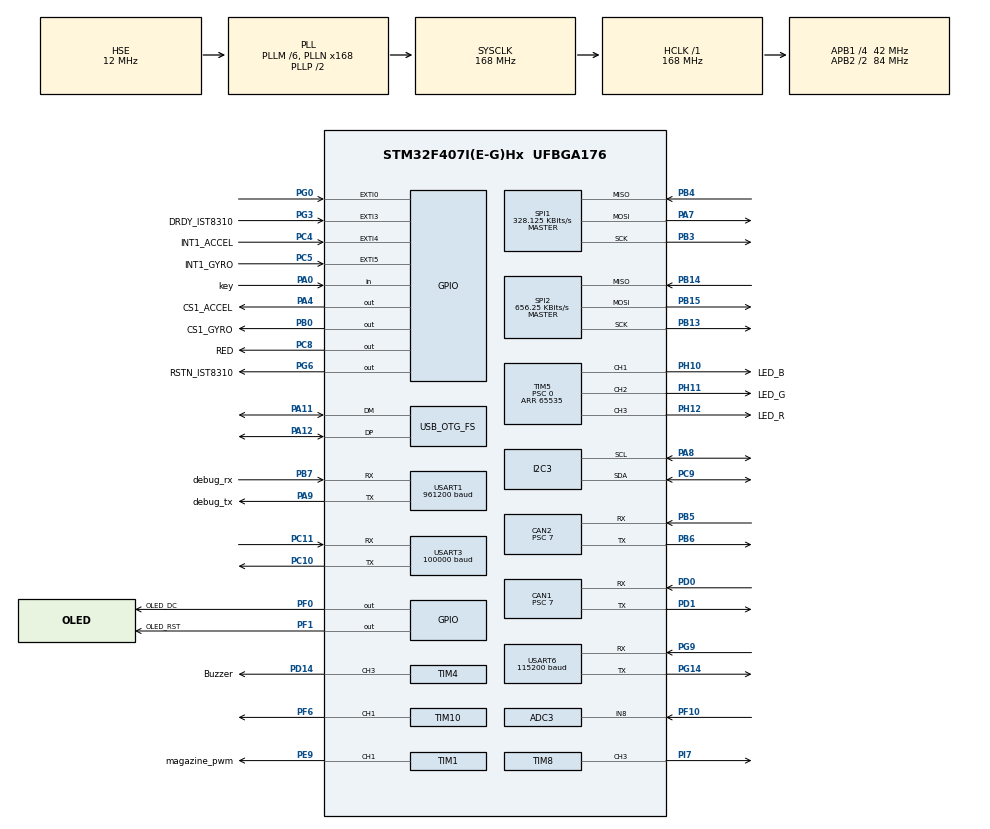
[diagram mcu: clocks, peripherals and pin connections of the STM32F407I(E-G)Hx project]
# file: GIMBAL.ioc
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ADC1.Channel-0\#ChannelRegularConversion=ADC_CHANNEL_TEMPSENSOR
ADC1.NbrOfConversionFlag=1
ADC1.Rank-0\#ChannelRegularConversion=1
ADC1.SamplingTime-0\#ChannelRegularConversion=ADC_SAMPLETIME_3CYCLES
ADC1.master=1
ADC3.Channel-0\#ChannelRegularConversion=ADC_CHANNEL_8
ADC3.NbrOfConversionFlag=1
ADC3.Rank-0\#ChannelRegularConversion=1
ADC3.SamplingTime-0\#ChannelRegularConversion=ADC_SAMPLETIME_3CYCLES
CAN1.ABOM=ENABLE
CAN1.AWUM=ENABLE
CAN1.BS1=CAN_BS1_3TQ
CAN1.BS2=CAN_BS2_2TQ
CAN1.CalculateTimeQuantum=166.66666666666669
CAN1.NART=ENABLE
CAN1.Prescaler=7
CAN2.ABOM=ENABLE
CAN2.AWUM=ENABLE
CAN2.BS1=CAN_BS1_3TQ
CAN2.BS2=CAN_BS2_2TQ
CAN2.CalculateTimeQuantum=166.66666666666669
CAN2.Prescaler=7
Dma.Request0=SPI1_RX
Dma.Request1=SPI1_TX
Dma.Request2=USART1_TX
Dma.Request3=USART3_RX
Dma.Request4=USART1_RX
Dma.Request5=USART6_RX
Dma.Request6=USART6_TX
Dma.Request7=TIM8_CH3
Dma.SPI1_RX.0.Direction=DMA_PERIPH_TO_MEMORY
Dma.SPI1_RX.0.FIFOMode=DMA_FIFOMODE_DISABLE
Dma.SPI1_RX.0.Instance=DMA2_Stream2
Dma.SPI1_RX.0.MemDataAlignment=DMA_MDATAALIGN_BYTE
Dma.SPI1_RX.0.MemInc=DMA_MINC_ENABLE
Dma.SPI1_RX.0.Mode=DMA_NORMAL
Dma.SPI1_RX.0.PeriphDataAlignment=DMA_PDATAALIGN_BYTE
Dma.SPI1_RX.0.PeriphInc=DMA_PINC_DISABLE
Dma.SPI1_RX.0.Priority=DMA_PRIORITY_VERY_HIGH
Dma.SPI1_TX.1.Direction=DMA_MEMORY_TO_PERIPH
Dma.SPI1_TX.1.FIFOMode=DMA_FIFOMODE_DISABLE
Dma.SPI1_TX.1.Instance=DMA2_Stream3
Dma.SPI1_TX.1.MemDataAlignment=DMA_MDATAALIGN_BYTE
Dma.SPI1_TX.1.MemInc=DMA_MINC_ENABLE
Dma.SPI1_TX.1.Mode=DMA_NORMAL
Dma.SPI1_TX.1.PeriphDataAlignment=DMA_PDATAALIGN_BYTE
Dma.SPI1_TX.1.PeriphInc=DMA_PINC_DISABLE
Dma.SPI1_TX.1.Priority=DMA_PRIORITY_HIGH
Dma.TIM8_CH3.7.Direction=DMA_MEMORY_TO_PERIPH
Dma.TIM8_CH3.7.FIFOMode=DMA_FIFOMODE_DISABLE
Dma.TIM8_CH3.7.Instance=DMA2_Stream4
Dma.TIM8_CH3.7.MemDataAlignment=DMA_MDATAALIGN_HALFWORD
Dma.TIM8_CH3.7.MemInc=DMA_MINC_ENABLE
Dma.TIM8_CH3.7.Mode=DMA_NORMAL
Dma.TIM8_CH3.7.PeriphDataAlignment=DMA_PDATAALIGN_HALFWORD
Dma.TIM8_CH3.7.PeriphInc=DMA_PINC_DISABLE
Dma.TIM8_CH3.7.Priority=DMA_PRIORITY_LOW
Dma.USART1_RX.4.Direction=DMA_PERIPH_TO_MEMORY
Dma.USART1_RX.4.FIFOMode=DMA_FIFOMODE_DISABLE
Dma.USART1_RX.4.Instance=DMA2_Stream5
Dma.USART1_RX.4.MemDataAlignment=DMA_MDATAALIGN_BYTE
Dma.USART1_RX.4.MemInc=DMA_MINC_ENABLE
Dma.USART1_RX.4.Mode=DMA_CIRCULAR
Dma.USART1_RX.4.PeriphDataAlignment=DMA_PDATAALIGN_BYTE
Dma.USART1_RX.4.PeriphInc=DMA_PINC_DISABLE
Dma.USART1_RX.4.Priority=DMA_PRIORITY_LOW
Dma.USART1_TX.2.Direction=DMA_MEMORY_TO_PERIPH
Dma.USART1_TX.2.FIFOMode=DMA_FIFOMODE_DISABLE
Dma.USART1_TX.2.Instance=DMA2_Stream7
Dma.USART1_TX.2.MemDataAlignment=DMA_MDATAALIGN_BYTE
Dma.USART1_TX.2.MemInc=DMA_MINC_ENABLE
Dma.USART1_TX.2.Mode=DMA_NORMAL
Dma.USART1_TX.2.PeriphDataAlignment=DMA_PDATAALIGN_BYTE
Dma.USART1_TX.2.PeriphInc=DMA_PINC_DISABLE
Dma.USART1_TX.2.Priority=DMA_PRIORITY_LOW
Dma.USART3_RX.3.Direction=DMA_PERIPH_TO_MEMORY
Dma.USART3_RX.3.FIFOMode=DMA_FIFOMODE_DISABLE
Dma.USART3_RX.3.Instance=DMA1_Stream1
Dma.USART3_RX.3.MemDataAlignment=DMA_MDATAALIGN_BYTE
Dma.USART3_RX.3.MemInc=DMA_MINC_ENABLE
Dma.USART3_RX.3.Mode=DMA_CIRCULAR
Dma.USART3_RX.3.PeriphDataAlignment=DMA_PDATAALIGN_BYTE
Dma.USART3_RX.3.PeriphInc=DMA_PINC_DISABLE
Dma.USART3_RX.3.Priority=DMA_PRIORITY_MEDIUM
Dma.USART6_RX.5.Direction=DMA_PERIPH_TO_MEMORY
Dma.USART6_RX.5.FIFOMode=DMA_FIFOMODE_DISABLE
Dma.USART6_RX.5.Instance=DMA2_Stream1
Dma.USART6_RX.5.MemDataAlignment=DMA_MDATAALIGN_BYTE
Dma.USART6_RX.5.MemInc=DMA_MINC_ENABLE
Dma.USART6_RX.5.Mode=DMA_CIRCULAR
Dma.USART6_RX.5.PeriphDataAlignment=DMA_PDATAALIGN_BYTE
Dma.USART6_RX.5.PeriphInc=DMA_PINC_DISABLE
Dma.USART6_RX.5.Priority=DMA_PRIORITY_MEDIUM
Dma.USART6_TX.6.Direction=DMA_MEMORY_TO_PERIPH
Dma.USART6_TX.6.FIFOMode=DMA_FIFOMODE_DISABLE
Dma.USART6_TX.6.Instance=DMA2_Stream6
Dma.USART6_TX.6.MemDataAlignment=DMA_MDATAALIGN_BYTE
Dma.USART6_TX.6.MemInc=DMA_MINC_ENABLE
Dma.USART6_TX.6.Mode=DMA_NORMAL
Dma.USART6_TX.6.PeriphDataAlignment=DMA_PDATAALIGN_BYTE
Dma.USART6_TX.6.PeriphInc=DMA_PINC_DISABLE
Dma.USART6_TX.6.Priority=DMA_PRIORITY_HIGH
FREERTOS.INCLUDE_eTaskGetState=1
FREERTOS.INCLUDE_pcTaskGetTaskName=1
FREERTOS.INCLUDE_uxTaskGetStackHighWaterMark=1
FREERTOS.INCLUDE_vTaskCleanUpResources=1
FREERTOS.INCLUDE_vTaskDelayUntil=1
FREERTOS.INCLUDE_xEventGroupSetBitFromISR=1
FREERTOS.INCLUDE_xQueueGetMutexHolder=1
FREERTOS.INCLUDE_xSemaphoreGetMutexHolder=1
FREERTOS.INCLUDE_xTaskAbortDelay=1
FREERTOS.INCLUDE_xTaskGetCurrentTaskHandle=1
FREERTOS.INCLUDE_xTaskGetHandle=1
FREERTOS.INCLUDE_xTimerPendFunctionCall=1
FREERTOS.Tasks01=test,0,128,test_task,As weak,NULL,Dynamic,NULL,NULL;Debug_Task,0,128,Debug,Default,NULL,Dynamic,NULL,NULL;IMU_Send_Task,2,128,IMU_Send,Default,NULL,Dynamic,NULL,NULL;Can2_Rei_Task,1,128,Can2_Reivece,Default,NULL,Dynamic,NULL,NULL;CAN1,1,128,CAN1_R,Default,NULL,Dynamic,NULL,NULL
FREERTOS.configTOTAL_HEAP_SIZE=24576
I2C3.I2C_Mode=I2C_Fast
Mcu.Family=STM32F4
Mcu.Name=STM32F407I(E-G)Hx
Mcu.Package=UFBGA176
NVIC.CAN1_RX0_IRQn=true\:5\:0\:true\:false\:true\:true\:true\:true
NVIC.CAN2_RX0_IRQn=true\:5\:0\:true\:false\:true\:true\:true\:true
NVIC.DMA1_Stream1_IRQn=true\:0\:0\:false\:false\:true\:false\:true\:true
NVIC.DMA2_Stream1_IRQn=true\:0\:0\:false\:false\:true\:true\:false\:true
NVIC.DMA2_Stream2_IRQn=true\:5\:0\:true\:false\:false\:false\:false\:false
NVIC.DMA2_Stream3_IRQn=true\:5\:0\:true\:false\:false\:true\:false\:true
NVIC.DMA2_Stream4_IRQn=true\:0\:0\:false\:false\:true\:true\:false\:true
NVIC.DMA2_Stream5_IRQn=true\:0\:0\:false\:false\:true\:true\:false\:true
NVIC.DMA2_Stream6_IRQn=true\:0\:0\:false\:false\:true\:true\:false\:true
NVIC.DMA2_Stream7_IRQn=true\:0\:0\:false\:false\:true\:false\:true\:true
NVIC.EXTI0_IRQn=true\:6\:0\:true\:false\:true\:true\:true\:true
NVIC.EXTI3_IRQn=true\:5\:0\:true\:false\:true\:true\:true\:true
NVIC.EXTI4_IRQn=true\:5\:0\:true\:false\:true\:true\:true\:true
NVIC.EXTI9_5_IRQn=true\:5\:0\:true\:false\:true\:true\:true\:true
NVIC.OTG_FS_IRQn=true\:5\:0\:true\:false\:true\:true\:true\:true
NVIC.PriorityGroup=NVIC_PRIORITYGROUP_4
NVIC.TIM3_IRQn=true\:7\:0\:true\:false\:true\:true\:true\:true
NVIC.TIM6_DAC_IRQn=true\:0\:0\:false\:false\:true\:false\:true\:true
NVIC.TimeBase=TIM6_DAC_IRQn
NVIC.TimeBaseIP=TIM6
NVIC.USART1_IRQn=true\:6\:0\:true\:false\:true\:true\:true\:true
NVIC.USART3_IRQn=true\:6\:0\:true\:false\:true\:true\:true\:true
NVIC.USART6_IRQn=true\:6\:0\:true\:false\:true\:true\:true\:true
PA0-WKUP.GPIO_Label=key
PA0-WKUP.GPIO_PuPd=GPIO_PULLUP
PA0-WKUP.Signal=GPIO_Input
PA11.Mode=Device_Only
PA11.Signal=USB_OTG_FS_DM
PA12.Mode=Device_Only
PA12.Signal=USB_OTG_FS_DP
PA13.Mode=Serial_Wire
PA13.Signal=SYS_JTMS-SWDIO
PA14.Mode=Serial_Wire
PA14.Signal=SYS_JTCK-SWCLK
PA4.GPIO_Label=CS1_ACCEL
PA4.GPIO_PuPd=GPIO_PULLUP
PA4.GPIO_Speed=GPIO_SPEED_FREQ_HIGH
PA4.PinState=GPIO_PIN_SET
PA4.Signal=GPIO_Output
PA7.GPIO_PuPd=GPIO_PULLUP
PA7.Mode=Full_Duplex_Master
PA7.Signal=SPI1_MOSI
PA8.Mode=I2C
PA8.Signal=I2C3_SCL
PA9.GPIO_Label=debug_tx
PA9.Mode=Asynchronous
PA9.Signal=USART1_TX
PB0.GPIO_Label=CS1_GYRO
PB0.GPIO_PuPd=GPIO_PULLUP
PB0.GPIO_Speed=GPIO_SPEED_FREQ_HIGH
PB0.PinState=GPIO_PIN_SET
PB0.Signal=GPIO_Output
PB12.Signal=SPI2_NSS
PB13.Mode=Full_Duplex_Master
PB13.Signal=SPI2_SCK
PB14.Mode=Full_Duplex_Master
PB14.Signal=SPI2_MISO
PB15.Mode=Full_Duplex_Master
PB15.Signal=SPI2_MOSI
PB3.GPIO_PuPd=GPIO_PULLUP
PB3.Mode=Full_Duplex_Master
PB3.Signal=SPI1_SCK
PB4.GPIO_PuPd=GPIO_PULLUP
PB4.Mode=Full_Duplex_Master
PB4.Signal=SPI1_MISO
PB5.Mode=Slave
PB5.Signal=CAN2_RX
PB6.Mode=Slave
PB6.Signal=CAN2_TX
PB7.GPIO_Label=debug_rx
PB7.Mode=Asynchronous
PB7.Signal=USART1_RX
PC10.Mode=Asynchronous
PC10.Signal=USART3_TX
PC11.Mode=Asynchronous
PC11.Signal=USART3_RX
PC4.GPIO_Label=INT1_ACCEL
PC4.GPIO_ModeDefaultEXTI=GPIO_MODE_IT_FALLING
PC4.GPIO_PuPd=GPIO_PULLUP
PC4.Signal=GPXTI4
PC5.GPIO_Label=INT1_GYRO
PC5.GPIO_ModeDefaultEXTI=GPIO_MODE_IT_FALLING
PC5.GPIO_PuPd=GPIO_PULLUP
PC5.Signal=GPXTI5
PC8.GPIO_Label=RED
PC8.GPIO_PuPd=GPIO_NOPULL
PC8.GPIO_Speed=GPIO_SPEED_FREQ_MEDIUM
PC8.Signal=GPIO_Output
PC9.Mode=I2C
PC9.Signal=I2C3_SDA
PD0.Mode=Master
PD0.Signal=CAN1_RX
PD1.Mode=Master
PD1.Signal=CAN1_TX
PD14.GPIO_Label=Buzzer
PD14.Signal=S_TIM4_CH3
PE9.GPIO_Label=magazine_pwm
PE9.Signal=S_TIM1_CH1
PF0.GPIO_Label=OLED_DC
PF0.Signal=GPIO_Output
PF1.GPIO_Label=OLED_RST
PF1.Signal=GPIO_Output
PF10.Mode=IN8
PF10.Signal=ADC3_IN8
PF6.GPIO_PuPd=GPIO_PULLUP
PF6.GPIO_Speed=GPIO_SPEED_FREQ_HIGH
PF6.Signal=S_TIM10_CH1
PG0.GPIO_ModeDefaultEXTI=GPIO_MODE_IT_FALLING
PG0.GPIO_PuPd=GPIO_PULLUP
PG0.Signal=GPXTI0
PG14.Mode=Asynchronous
PG14.Signal=USART6_TX
PG3.GPIO_Label=DRDY_IST8310
PG3.GPIO_ModeDefaultEXTI=GPIO_MODE_IT_FALLING
PG3.GPIO_PuPd=GPIO_PULLUP
PG3.Signal=GPXTI3
PG6.GPIO_Label=RSTN_IST8310
PG6.GPIO_PuPd=GPIO_PULLUP
PG6.GPIO_Speed=GPIO_SPEED_FREQ_MEDIUM
PG6.PinState=GPIO_PIN_SET
PG6.Signal=GPIO_Output
PG9.Mode=Asynchronous
PG9.Signal=USART6_RX
PH0-OSC_IN.Mode=HSE-External-Oscillator
PH0-OSC_IN.Signal=RCC_OSC_IN
PH1-OSC_OUT.Mode=HSE-External-Oscillator
PH1-OSC_OUT.Signal=RCC_OSC_OUT
PH10.GPIO_Label=LED_B
PH10.GPIO_PuPd=GPIO_PULLUP
PH10.GPIO_Speed=GPIO_SPEED_FREQ_HIGH
PH10.Signal=S_TIM5_CH1
PH11.GPIO_Label=LED_G
PH11.GPIO_PuPd=GPIO_PULLUP
PH11.GPIO_Speed=GPIO_SPEED_FREQ_HIGH
PH11.Signal=S_TIM5_CH2
PH12.GPIO_Label=LED_R
PH12.GPIO_PuPd=GPIO_PULLUP
PH12.GPIO_Speed=GPIO_SPEED_FREQ_HIGH
PH12.Signal=S_TIM5_CH3
PI7.Signal=S_TIM8_CH3
ProjectManager.HeapSize=0x2000
ProjectManager.StackSize=0x2000
ProjectManager.TargetToolchain=MDK-ARM V5
RCC.48MHZClocksFreq_Value=48000000
RCC.AHBFreq_Value=168000000
RCC.APB1CLKDivider=RCC_HCLK_DIV4
RCC.APB1Freq_Value=42000000
RCC.APB1TimFreq_Value=84000000
RCC.APB2CLKDivider=RCC_HCLK_DIV2
RCC.APB2Freq_Value=84000000
RCC.APB2TimFreq_Value=168000000
RCC.CortexFreq_Value=168000000
RCC.HCLKFreq_Value=168000000
RCC.HSE_VALUE=12000000
RCC.HSI_VALUE=16000000
RCC.LSE_VALUE=32768
RCC.PLLM=6
RCC.PLLN=168
RCC.PLLQ=7
RCC.RCC_RTC_Clock_SourceVirtual=RCC_RTCCLKSOURCE_HSE_DIV30
RCC.RCC_RTC_Clock_Source_FROM_HSE=RCC_RTCCLKSOURCE_HSE_DIV30
RCC.SYSCLKFreq_VALUE=168000000
RCC.SYSCLKSource=RCC_SYSCLKSOURCE_PLLCLK
RCC.VCOOutputFreq_Value=336000000
SH.S_TIM10_CH1.0=TIM10_CH1,PWM Generation1 CH1
SH.S_TIM1_CH1.0=TIM1_CH1,PWM Generation1 CH1
SH.S_TIM4_CH3.0=TIM4_CH3,PWM Generation3 CH3
SH.S_TIM5_CH1.0=TIM5_CH1,PWM Generation1 CH1
SH.S_TIM5_CH2.0=TIM5_CH2,PWM Generation2 CH2
SH.S_TIM5_CH3.0=TIM5_CH3,PWM Generation3 CH3
SH.S_TIM8_CH3.0=TIM8_CH3,PWM Generation3 CH3
SPI1.BaudRatePrescaler=SPI_BAUDRATEPRESCALER_256
SPI1.CLKPhase=SPI_PHASE_2EDGE
SPI1.CLKPolarity=SPI_POLARITY_HIGH
SPI1.CalculateBaudRate=328.125 KBits/s
SPI1.Direction=SPI_DIRECTION_2LINES
SPI1.Mode=SPI_MODE_MASTER
SPI1.VirtualType=VM_MASTER
SPI2.BaudRatePrescaler=SPI_BAUDRATEPRESCALER_64
SPI2.CalculateBaudRate=656.25 KBits/s
SPI2.Direction=SPI_DIRECTION_2LINES
SPI2.Mode=SPI_MODE_MASTER
SPI2.VirtualType=VM_MASTER
TIM1.Channel-PWM\ Generation1\ CH1=TIM_CHANNEL_1
TIM1.Period=19999
TIM1.Prescaler=83
TIM10.Channel=TIM_CHANNEL_1
TIM10.Period=4999
TIM3.AutoReloadPreload=TIM_AUTORELOAD_PRELOAD_ENABLE
TIM3.Period=49
TIM3.Prescaler=83
TIM4.Channel-PWM\ Generation3\ CH3=TIM_CHANNEL_3
TIM4.Period=370
TIM4.Prescaler=130
TIM4.Pulse-PWM\ Generation3\ CH3=0
TIM5.Channel-PWM\ Generation1\ CH1=TIM_CHANNEL_1
TIM5.Channel-PWM\ Generation2\ CH2=TIM_CHANNEL_2
TIM5.Channel-PWM\ Generation3\ CH3=TIM_CHANNEL_3
TIM5.Period=65535
TIM5.Prescaler=0
TIM8.Channel-PWM\ Generation3\ CH3=TIM_CHANNEL_3
TIM8.Period=224
USART1.BaudRate=961200
USART1.VirtualMode=VM_ASYNC
USART3.BaudRate=100000
USART3.VirtualMode=VM_ASYNC
USART6.BaudRate=115200
USART6.VirtualMode=VM_ASYNC
USB_DEVICE.CLASS_NAME_FS=CDC
USB_DEVICE.VirtualMode-CDC_FS=Cdc
USB_DEVICE.VirtualModeFS=Cdc_FS
USB_OTG_FS.VirtualMode=Device_Only
VP_ADC1_TempSens_Input.Mode=IN-TempSens
VP_ADC1_Vref_Input.Mode=IN-Vrefint
VP_FREERTOS_VS_CMSIS_V1.Mode=CMSIS_V1
VP_SYS_VS_tim6.Mode=TIM6
VP_TIM10_VS_ClockSourceINT.Mode=Enable_Timer
VP_TIM1_VS_ClockSourceINT.Mode=Internal
VP_TIM3_VS_ClockSourceINT.Mode=Internal
VP_TIM4_VS_ClockSourceINT.Mode=Internal
VP_TIM5_VS_ClockSourceINT.Mode=Internal
VP_TIM8_VS_ClockSourceINT.Mode=Internal
VP_USB_DEVICE_VS_USB_DEVICE_CDC_FS.Mode=CDC_FS
board=custom

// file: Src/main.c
/* USER CODE BEGIN Header */
/**
  ******************************************************************************
  * @file           : main.c
  * @brief          : Main program body
  ******************************************************************************
  * @attention
  *
  * <h2><center>&copy; Copyright (c) 2019 STMicroelectronics.
  * All rights reserved.</center></h2>
  *
  * This software component is licensed by ST under Ultimate Liberty license
  * SLA0044, the "License"; You may not use this file except in compliance with
  * the License. You may obtain a copy of the License at:
  *                             www.st.com/SLA0044
  *
  ******************************************************************************
  */
/* USER CODE END Header */
#include "main.h"
#include "cmsis_os.h"
#include "adc.h"
#include "can.h"
#include "dma.h"
#include "i2c.h"
#include "spi.h"
#include "tim.h"
#include "usart.h"
#include "usb_device.h"
#include "gpio.h"

/* USER CODE BEGIN Includes */
#include "bsp_delay.h"

#include "calibrate_task.h"
#include "INS_task.h"
#include "led_flow_task.h"
#include "user_can.h"
#include "bsp_buzzer.h"
#include "stdbool.h"
#include "DR16_RECIVE.h"
#include "oled.h"
#include "bsp_adc.h"
#include "stdio.h"
#include "WS2812.h"

//#include "oledfont.h"
/* USER CODE END Includes */

void SystemClock_Config(void);
void MX_FREERTOS_Init(void);

/* USER CODE BEGIN 0 */
bool ins_ok=0;
int controul_times=0;
int ins_times=0;
int DR16_times=0;
int M2006_times=0;

int send_to_2006=0;
int M2006_targe_speed=0;
int beep_Val=0;

	int	send_to_SHOOT_R=0;
	int	send_to_SHOOT_L=0;

int SHOOT_L_speed=0;//左摩擦轮的目标速度   应该为负值
int SHOOT_R_speed=0;//右摩擦轮的目标速度

int yaw_trage_speed=0;
float yaw_trage_angle=0;
float yaw_trage_angle_1s_ago=0;
float yaw_trage_angle_add_1s=0;
float yaw_trage_angle_new=0;
float yaw_trage_angle_new_2=0;
float yaw_trage_angle_new_motor=0;//目标角度（电机）

int send_to_yaw=0;

int send_to_pitch=0;//发送给pitch轴的数据

float PITCH_MAX_angle=0;
float PITCH_MIN_angle=0;
float allow_angle=0;//可动区间

float PITCH_trage_angle=0;
float PITCH_trage_angle_motor=4500.0;

int PITCH_trage_speed=0;

int can1_IT_TIMES=0;

int can2_DR16_TIMES=0;
int can2_IT_TIMES=0;
int CH0_TOTAL=0;
int CH0_TOTAL_in_con=0;

int CH1_TOTAL=0;
int CH2_TOTAL=0;
int CH3_TOTAL=0;

int JS_RC_TIMES=0;
int JS_SHOOT_RC_TIMES_FOR_FPS=0;
int JS_SHOOT_RC_TIMES_100MSms=0;

bool run_JS_jiema;

int STATUS_PART_ONE_TIMES=0;
int STATUS_PART_TWO_TIMES=0;
int STATUS_PART_THREE_TIMES=0;
int STATUS_PART_FOUR_TIMES=0;
int STATUS_complete_update_TIMES=0;//裁判系统状态信息更新成功次数

int HP_complete_update_TIMES=0;//裁判系统状态信息更新成功次数

int HEAT_complete_update_TIMES=0;//裁判系统热量信息更新成功次数
int place_complete_update_TIMES=0;//裁判系统热量信息更新成功次数

int GAME_STATE_update_TIMES=0;//裁判系统比赛状态信息更新成功次数

int DDR16_PART_ONE_TIMES=0;
int DDR16_PART_TWO_TIMES=0;
int DDR16_PART_THREE_TIMES=0;
int dr16_controul_times=0;
bool run_DR16_jiema;

float Vision_RawData_Yaw_Angle=0;
float Vision_RawData_Pitch_Angle=0;
volatile unsigned long long FreeRTOSRunTimeTicks;

int TEST_Current_L=0;
int TEST_Current_R=0;

int CLOUD_enable_moto=0;
float CLOUD_enable_imu=0;
bool cloud_text_add=1;
bool cloud_enable=0;
int VISION_FROM_USART1=0;
int VISION_Disconnect_test=0;
int Armour_lose_time=0;
int SHOOT_STOP_time=0;

int vision_shoot_times;
int shoot_times_for_limit=0;//发射周期(为了热量限制)
bool whether_shoot_in__this_period=0;//这个周期是否发射
bool this_period_has_shoot=0;//这个周期是否发射

int this_period_has_shoot_number=0;//这个周期发射shu
int every_shoot_number=600;//一次三十发
int targe_shoot_number=0;//一次三十发

bool disable_for_test=0;//为了调试
int ch4_DW_total=0;
int ch4_DW_total_2=0;

bool crc_right=0;
int vision_rc_right=0;
int vision_rc_error=0;

int CAN2_rc_times=0;

float simulation_target_yaw=0;

bool TEMPERATURE_is_OK=0;
int TEMPERATURE_PID_OUT=0;

bool in_MID=1;//处在轨道中间段
bool in_END=0;//处在轨道尽头
bool in_END_last=0;//上一时刻处在轨道尽头

bool in_END_R=0;//处在右轨道尽头
bool in_END_L=0;//处在左轨道尽头

bool disable_for_test_CHASSIS=0;

float my_voltage;

int stay_in_track_end_times=0;
int text_times=0;

bool send_to_vision_1=0;

int hurt_times_ago=100000;
int laoliu_gjiwo_times_ago=100000;//老六攻击我
float jia_ZJ_YAW=0;
float jia_ZJ_PITCH=-40.0;
bool vision_beats_give_to_jia=0;

/*假装甲要用到GEBIN*/
 int8_t whether_use_fake_armor=0;
int fake_armor_init_angle_6020=0;
int fake_armor_init_place_encoder=0;
int fake_armor_vertical_place_encoder=0;

int fake_armor_init_vision_deepth=0;/*mm*/
int fake_armor_vertica_distance=0;/*垂直距离mm*/

float fake_armor_now_angle_IMU=0.0;

float YAW_TRAGET_ANGLE_TEMP_FAKE_MOTO;
float YAW_TRAGET_ANGLE_TEMP_FAKE_IMU;

float send_to_pitch_before=0;
/*假装甲要用到END*/
uint16_t mag_on =  3700;
uint16_t mag_text = 3000;
uint16_t mag_off = 2200;

int MAX_HOT_SHOOT=50;
int MAX_SPEE_SHOOT=15;

int stop_shoot_times_new=0;

float mouse_x_attenuation=900;
float mouse_y_attenuation=150;

/* USER CODE END 0 */

int main(void)
{

  /* MCU Configuration--------------------------------------------------------*/

  /* Reset of all peripherals, Initializes the Flash interface and the Systick. */
  HAL_Init();

  /* Configure the system clock */
  SystemClock_Config();

  /* Initialize all configured peripherals */
  MX_GPIO_Init();
  MX_DMA_Init();
  MX_SPI1_Init();
  MX_TIM5_Init();
  MX_I2C3_Init();
  MX_TIM10_Init();
  MX_USART1_UART_Init();
  MX_CAN2_Init();
  MX_TIM4_Init();
  MX_USART3_UART_Init();
  MX_CAN1_Init();
  MX_TIM3_Init();
  MX_USART6_UART_Init();
  MX_SPI2_Init();
  MX_ADC1_Init();
  MX_ADC3_Init();
  MX_TIM1_Init();
  MX_TIM8_Init();
  /* USER CODE BEGIN 2 */
	  delay_init();
		Buzzer_Init();
//					Buzzer.status = ON;

    cali_param_init();
   usart1_dr16_init();
   #ifdef FREERTOS_TASK_TIME
       HAL_TIM_Base_Start_IT(&htim3);
#endif
  oled_init();
  HAL_Delay(500);
//
ws2812_init(8);

    oled_clear(Pen_Clear);
    oled_LOGO();
    oled_refresh_gram();

    //use vrefint voltage to calibrate
    //使用基准电压来校准
    init_vrefint_reciprocal();

//CAN1_Config();
  /* USER CODE END 2 */

  /* Call init function for freertos objects (in freertos.c) */
  MX_FREERTOS_Init();
  /* Start scheduler */
  osKernelStart();

  /* We should never get here as control is now taken by the scheduler */
  /* Infinite loop */
  while (1)
  {

  }
}

void SystemClock_Config(void)
{
  RCC_OscInitTypeDef RCC_OscInitStruct = {0};
  RCC_ClkInitTypeDef RCC_ClkInitStruct = {0};

  /** Configure the main internal regulator output voltage
  */
  __HAL_RCC_PWR_CLK_ENABLE();
  __HAL_PWR_VOLTAGESCALING_CONFIG(PWR_REGULATOR_VOLTAGE_SCALE1);
  /** Initializes the RCC Oscillators according to the specified parameters
  * in the RCC_OscInitTypeDef structure.
  */
  RCC_OscInitStruct.OscillatorType = RCC_OSCILLATORTYPE_HSE;
  RCC_OscInitStruct.HSEState = RCC_HSE_ON;
  RCC_OscInitStruct.PLL.PLLState = RCC_PLL_ON;
  RCC_OscInitStruct.PLL.PLLSource = RCC_PLLSOURCE_HSE;
  RCC_OscInitStruct.PLL.PLLM = 6;
  RCC_OscInitStruct.PLL.PLLN = 168;
  RCC_OscInitStruct.PLL.PLLP = RCC_PLLP_DIV2;
  RCC_OscInitStruct.PLL.PLLQ = 7;
  if (HAL_RCC_OscConfig(&RCC_OscInitStruct) != HAL_OK)
  {
    Error_Handler();
  }
  /** Initializes the CPU, AHB and APB buses clocks
  */
  RCC_ClkInitStruct.ClockType = RCC_CLOCKTYPE_HCLK|RCC_CLOCKTYPE_SYSCLK
                              |RCC_CLOCKTYPE_PCLK1|RCC_CLOCKTYPE_PCLK2;
  RCC_ClkInitStruct.SYSCLKSource = RCC_SYSCLKSOURCE_PLLCLK;
  RCC_ClkInitStruct.AHBCLKDivider = RCC_SYSCLK_DIV1;
  RCC_ClkInitStruct.APB1CLKDivider = RCC_HCLK_DIV4;
  RCC_ClkInitStruct.APB2CLKDivider = RCC_HCLK_DIV2;

  if (HAL_RCC_ClockConfig(&RCC_ClkInitStruct, FLASH_LATENCY_5) != HAL_OK)
  {
    Error_Handler();
  }
}

/* USER CODE BEGIN 4 */
//初始化TIM3使其为FreeRTOS的时间统计提供时基
void ConfigureTimeForRunTimeStats(void)
{
	//定时器3初始化，定时器时钟为84M，分频系数为84-1，所以定时器3的频率
	//为84M/84=1M，自动重装载为50-1，那么定时器周期就是50us
	FreeRTOSRunTimeTicks=0;
//	TIM3_Int_Init(50-1,84-1);	//初始化TIM3
}

//int fputc(int ch, FILE *f)
//{
// uint8_t temp[1] = {ch};
// HAL_UART_Transmit(&huart1, temp, 1, 100);
// return ch;
//}

/* USER CODE END 4 */

void HAL_TIM_PeriodElapsedCallback(TIM_HandleTypeDef *htim)
{
  if (htim->Instance == TIM6) {
    HAL_IncTick();
  }
}

void Error_Handler(void)
{
}

/************************ (C) COPYRIGHT STMicroelectronics *****END OF FILE****/

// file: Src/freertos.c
/* USER CODE BEGIN Header */
/**
 ******************************************************************************
 * File Name          : freertos.c
 * Description        : Code for freertos applications
 ******************************************************************************
 * @attention
 *
 * <h2><center>&copy; Copyright (c) 2019 STMicroelectronics.
 * All rights reserved.</center></h2>
 *
 * This software component is licensed by ST under Ultimate Liberty license
 * SLA0044, the "License"; You may not use this file except in compliance with
 * the License. You may obtain a copy of the License at:
 *                             www.st.com/SLA0044
 *
 ******************************************************************************
 */
/* USER CODE END Header */

#include "FreeRTOS.h"
#include "task.h"
#include "main.h"
#include "cmsis_os.h"

/* USER CODE BEGIN Includes */

#include "calibrate_task.h"

#include "INS_task.h"
#include "led_flow_task.h"
#include "usbd_cdc_if.h"

#include "Debug_DataScope.h"
#include "DJI_IMU.h"
#include "bsp_buzzer.h"
#include "M3508.h"
#include "M2006.h"
#include "my_IncrementPID_bate.h"
#include "DR16_RECIVE.h"
#include "my_positionPID_bate.h"
#include "GM6020.h"
#include "MY_CLOUD_CONTROL.h"
#include "MY_SHOOT_CONTROL.h"
#include "BEEP_MY.h"
#include "bsp_buzzer.h"
#include "Vision.h"
#include "string.h"
#include "FPS_Calculate.h"
#include "bsp_adc.h"
#include "oled.h"
#include "spinning_top_examine.h"
#include "Vision_Control.h"
#include "MY_CLOUD_CONTROL.h"
#include "CAN2_SEND.h"
#include "keyBoard_to_vjoy.h"
#include "WS2812.h"

//#include "usbd_cdc_if.h"

/* USER CODE END Includes */

/* USER CODE BEGIN PTD */

osThreadId calibrate_tast_handle;
osThreadId imuTaskHandle;
osThreadId led_RGB_flow_handle;

/* USER CODE END PTD */

/* USER CODE BEGIN Variables */
// CAN队列句柄
osMessageQId CAN1_Queue;

osMessageQId CAN2_Queue;

//控制任务句柄
osThreadId RobotCtrl_Handle;
//任务入口函数
void Robot_Control(void const *argument);

/* USER CODE END Variables */
osThreadId testHandle;
osThreadId Debug_TaskHandle;
osThreadId IMU_Send_TaskHandle;
osThreadId Can2_Rei_TaskHandle;
osThreadId CAN1Handle;

void test_task(void const * argument);
void Debug(void const * argument);
void IMU_Send(void const * argument);
void Can2_Reivece(void const * argument);
void CAN1_R(void const * argument);

extern void MX_USB_DEVICE_Init(void);
void MX_FREERTOS_Init(void); /* (MISRA C 2004 rule 8.1) */

/* GetIdleTaskMemory prototype (linked to static allocation support) */
void vApplicationGetIdleTaskMemory( StaticTask_t **ppxIdleTaskTCBBuffer, StackType_t **ppxIdleTaskStackBuffer, uint32_t *pulIdleTaskStackSize );

/* GetTimerTaskMemory prototype (linked to static allocation support) */
void vApplicationGetTimerTaskMemory( StaticTask_t **ppxTimerTaskTCBBuffer, StackType_t **ppxTimerTaskStackBuffer, uint32_t *pulTimerTaskStackSize );

/* USER CODE BEGIN GET_IDLE_TASK_MEMORY */
static StaticTask_t xIdleTaskTCBBuffer;
static StackType_t xIdleStack[configMINIMAL_STACK_SIZE];

void vApplicationGetIdleTaskMemory(StaticTask_t **ppxIdleTaskTCBBuffer, StackType_t **ppxIdleTaskStackBuffer, uint32_t *pulIdleTaskStackSize)
{
	*ppxIdleTaskTCBBuffer = &xIdleTaskTCBBuffer;
	*ppxIdleTaskStackBuffer = &xIdleStack[0];
	*pulIdleTaskStackSize = configMINIMAL_STACK_SIZE;
	/* place for user code */
}
/* USER CODE END GET_IDLE_TASK_MEMORY */

/* USER CODE BEGIN GET_TIMER_TASK_MEMORY */
static StaticTask_t xTimerTaskTCBBuffer;
static StackType_t xTimerStack[configTIMER_TASK_STACK_DEPTH];

void vApplicationGetTimerTaskMemory(StaticTask_t **ppxTimerTaskTCBBuffer, StackType_t **ppxTimerTaskStackBuffer, uint32_t *pulTimerTaskStackSize)
{
	*ppxTimerTaskTCBBuffer = &xTimerTaskTCBBuffer;
	*ppxTimerTaskStackBuffer = &xTimerStack[0];
	*pulTimerTaskStackSize = configTIMER_TASK_STACK_DEPTH;
	/* place for user code */
}
/* USER CODE END GET_TIMER_TASK_MEMORY */

void MX_FREERTOS_Init(void) {
  /* USER CODE BEGIN Init */

		  HAL_Delay(500);

//		ws2812_red(8);

	I_PID_Parameter_Init(&Driver_I_PID, 4, 0.2, 5,
						 20000,		  //积分分离
						 9000, -9000, //最大误差
						 0.5,
						 9000, -9000,
						 10000, -10000); //拨盘电机
	P_PID_Parameter_Init(&Driver_ANGLE_pid, 0.3, 0, 0,
						 3000,
						 // float max_error, float min_error,
						 //                           float alpha,
						 2000, -2000,
						 7000, -7000);
#if 0 //15m/s的参数
	I_PID_Parameter_Init(&SHOOT_L_I_PID, 23, 0.30, 13,
						 8700, 7000, -7000,
						 0.5,
						 14000, -14000,
						 16000, -16000); //摩擦轮电机 37 0.35 13

	//
	I_PID_Parameter_Init(&SHOOT_R_I_PID, 20, 0.3, 28,
						 20000, 20000, -20000,
						 0.5,
						 14000, -14000,
						 16000, -16000); //摩擦轮电机28 0.35 15
						 //23 0.5 19
						 //22 0.35 19
#endif
#if 1 //15m/s的参数
	I_PID_Parameter_Init(&SHOOT_L_I_PID, 20, 0.30, 28,
						 8700, 7000, -7000,
						 0.5,
						 14000, -14000,
						 16000, -16000); //摩擦轮电机 37 0.35 13

	//
	I_PID_Parameter_Init(&SHOOT_R_I_PID, 20, 0.3, 28,
						 20000, 20000, -20000,
						 0.5,
						 14000, -14000,
						 16000, -16000); //摩擦轮电机28 0.35 15
						 //23 0.5 19
						 //22 0.35 19
#endif
#if 0 //30m/s的参数
	I_PID_Parameter_Init(&SHOOT_L_I_PID, 28, 0.35, 15,
						 8700, 7000, -7000,
						 0.5,
						 14000, -14000,
						 16000, -16000); //摩擦轮电机 37 0.35 13

	//
	I_PID_Parameter_Init(&SHOOT_R_I_PID, 28,0.35, 15,
						 8700, 7000, -7000,
						 0.5,
						 14000, -14000,
						 16000, -16000); //摩擦轮电机28 0.35 15
						 //23 0.5 19
						 //22 0.35 19
#endif
#if PID_MOTOR //是否开启电机的PID
	P_PID_Parameter_Init(&Yaw_Speed_pid, 550, 10, 0,
						 120, //误差大于这个值就积分分离
						 //	float max_error, float min_error,
						 //                          float alpha,
						 2000, -2000, //积分限幅，也就是积分的输出范围
						 29000, -29000);
	P_PID_Parameter_Init(&Yaw_Angle_pid, 0.03, 0, 0,
						 0,
						 //						  float max_error, float min_error,
						 //                          float alpha,
						 0, 0,
						 220, -220); //

#endif

#if PID_YAW_IMU
	P_PID_Parameter_Init(&Yaw_IMU_Speed_pid, -400, -4, 100,//
						 120, //误差大于这个值就积分分离
						 //	float max_error, float min_error,
						 //                          float alpha,
						 2000, -2000, //积分限幅，也就是积分的输出范围
						 29000, -29000);

	P_PID_Parameter_Init(&Yaw_IMU_Angle_pid, 15, 0, -15,//10 0 16//越大越陡峭10
						 30,
						 //						  float max_error, float min_error,
						 //                          float alpha,
						 10, -10,
						 1000, -1000); // Yaw_IMU_Angle_pid
#endif

#if VISION_PID_YAW_IMU

	P_PID_Parameter_Init(&VISION_Yaw_IMU_Speed_pid, -900, -4.5, 800,//
						 60, //误差大于这个值就积分分离
						 //	float max_error, float min_error,
						 //                          float alpha,
						 5000, -5000, //积分限幅，也就是积分的输出范围
						 29000, -29000);

	P_PID_Parameter_Init(&VISION_Yaw_IMU_Angle_pid, 10, 0.085, 0,//10 0 16//越大越陡峭10
						 2.8,
						 //						  float max_error, float min_error,
						 //                          float alpha,
						 600, -600,
						 1000, -1000); // Yaw_IMU_Angle_pid

#endif

#if use_new_gimbal==0
#if PID_PITCH_MOTOR
	P_PID_Parameter_Init(&PITCH_Angle_pid, 0.45, 0, 0,
						 0, //误差大于这个值就积分分离
						 //	float max_error, float min_error,
						 //                          float alpha,
						 220, -220, //积分限幅，也就是积分的输出范围
						 220, -220);
	P_PID_Parameter_Init(&PITCH_Speed_pid, 300, 1, 0,
						 120,
						 //						  float max_error, float min_error,
						 //                          float alpha,
						 10000, -10000,	 //积分限幅，也就是积分的输出范围
						 29000, -29000); // Yaw_IMU_Angle_pid
#endif

#endif
#if use_new_gimbal==1
#if PID_PITCH_MOTOR
	P_PID_Parameter_Init(&PITCH_Angle_pid, 0.7, 0.05, 0,
						 0, //误差大于这个值就积分分离
						 //	float max_error, float min_error,
						 //                          float alpha,
						 220, -220, //积分限幅，也就是积分的输出范围
						 220, -220);
	P_PID_Parameter_Init(&PITCH_Speed_pid, 300, 1, 0,
						 120,
						 //						  float max_error, float min_error,
						 //                          float alpha,
						 10000, -10000,	 //积分限幅，也就是积分的输出范围
						 29000, -29000); // Yaw_IMU_Angle_pid
#endif
#endif
#if use_balance_gimbal==1
#if PID_PITCH_MOTOR
	P_PID_Parameter_Init(&PITCH_Angle_pid,1.6, 0.09, -1,
						 0, //误差大于这个值就积分分离
						 //	float max_error, float min_error,
						 //                          float alpha,
						 220, -220, //积分限幅，也就是积分的输出范围
						 220, -220);
	P_PID_Parameter_Init(&PITCH_Speed_pid, 50, 0.32, -40,
						 120,
						 //						  float max_error, float min_error,
						 //                          float alpha,
						 10000, -10000,	 //积分限幅，也就是积分的输出范围
						 29000, -29000); // Yaw_IMU_Angle_pid
#endif
#endif

#if 0//没电参数
	P_PID_Parameter_Init(&PITCH_IMU_Speed_pid, 200,0.4,0,//100, 1.5, 0,
						 15, //误差大于这个值就积分分离  550 1.9 0   -20000
						 //	float max_error, float min_error,
						 //                          float alpha,
						 3000, -3000, //积分限幅，也就是积分的输出范围    80    0.7        5000   -5000     28000   -28000
						 29000, -29000);
	P_PID_Parameter_Init(&PITCH_IMU_Angle_pid,12 //15  //0.7  12
	, 0.1, 0,
						 2.5,
						 //						  float max_error, float min_error,
						 //                          float alpha,
						 300, -300,
						 500, -500); // Yaw_IMU_Angle_pid   15    500 -500

#endif
#if PID_PITCH_IMU
//	P_PID_Parameter_Init(&PITCH_IMU_Speed_pid, 150,0.3,0,//100, 1.5, 0,
//						 25, //误差大于这个值就积分分离  550 1.9 0   -20000
//						 //	float max_error, float min_error,
//						 //                          float alpha,
//						 4000, -4000, //积分限幅，也就是积分的输出范围    80    0.7        5000   -5000     28000   -28000
//						 29000, -29000);

	P_PID_Parameter_Init(&PITCH_IMU_Speed_pid, 80,0.1,-30,//100, 1.5, 0,
						 100, //误差大于这个值就积分分离  550 1.9 0   -20000
						 //	float max_error, float min_error,
						 //                          float alpha,
						 4000, -4000, //积分限幅，也就是积分的输出范围    80    0.7        5000   -5000     28000   -28000
						 29000, -29000);
	P_PID_Parameter_Init(&PITCH_IMU_Angle_pid,9 //15  //0.7  12
	, 0.08, 0,
						 2.5,
						 //						  float max_error, float min_error,
						 //                          float alpha,
						 300, -300,
						 500, -500); // Yaw_IMU_Angle_pid   15    500 -500

#endif
Vision_Control_Init();//卡尔曼参数初始化

  /* USER CODE END Init */

  /* USER CODE BEGIN RTOS_MUTEX */
	/* add mutexes, ... */

		CAN1_Config();
//	CAN1_Filter0_Init();
//
//	__HAL_CAN_ENABLE_IT(&hcan1, CAN_IT_RX_FIFO0_MSG_PENDING);

//	HAL_CAN_Start(&hcan1);

		CAN2_Config();
			//视觉
	__HAL_UART_CLEAR_IDLEFLAG(&huart6);

	__HAL_UART_ENABLE_IT(&huart6, UART_IT_IDLE);

	USART_RX_DMA_ENABLE(&huart6, Vision_DataBuff, Vision_BuffSize);
					ext_robot_hurt.data.hurt_type=10;//避免初始值为0误识别

    HAL_TIM_PWM_Start(&htim1, TIM_CHANNEL_1);
    __HAL_TIM_SetCompare(&htim1, TIM_CHANNEL_1, mag_text);

//DJIC_IMU.pitch_turnCounts=-1;
	//CAN2_Filter0 初始化 使能
//	  HAL_Delay(1000);

//	CAN2_Filter0_Init();
//

//	__HAL_CAN_ENABLE_IT(&hcan2, CAN_IT_RX_FIFO0_MSG_PENDING);

//			HAL_CAN_Start(&hcan2);

  /* USER CODE END RTOS_MUTEX */

  /* USER CODE BEGIN RTOS_QUEUES */
	/* add queues, ... */
	CAN2_Queue = xQueueCreate(64, sizeof(CAN_Rx_TypeDef));
	CAN1_Queue = xQueueCreate(32, sizeof(CAN_Rx_TypeDef));
  MX_USB_DEVICE_Init();

  /* USER CODE END RTOS_QUEUES */

  /* Create the thread(s) */
  /* definition and creation of test */
  osThreadDef(test, test_task, osPriorityNormal, 0, 128);
  testHandle = osThreadCreate(osThread(test), NULL);

  /* definition and creation of Debug_Task */
  osThreadDef(Debug_Task, Debug, osPriorityNormal, 0, 128);
  Debug_TaskHandle = osThreadCreate(osThread(Debug_Task), NULL);

  /* definition and creation of IMU_Send_Task */
  osThreadDef(IMU_Send_Task, IMU_Send, osPriorityHigh, 0, 128);
  IMU_Send_TaskHandle = osThreadCreate(osThread(IMU_Send_Task), NULL);

  /* definition and creation of Can2_Rei_Task */
  osThreadDef(Can2_Rei_Task, Can2_Reivece, osPriorityAboveNormal, 0, 128);
  Can2_Rei_TaskHandle = osThreadCreate(osThread(Can2_Rei_Task), NULL);

  /* definition and creation of CAN1 */
  osThreadDef(CAN1, CAN1_R, osPriorityAboveNormal, 0, 128);
  CAN1Handle = osThreadCreate(osThread(CAN1), NULL);

  /* USER CODE BEGIN RTOS_THREADS */
	/* add threads, ... */
	osThreadDef(cali, calibrate_task, osPriorityAboveNormal, 0, 512);
	calibrate_tast_handle = osThreadCreate(osThread(cali), NULL);

	osThreadDef(imuTask, INS_task, osPriorityRealtime, 0, 1024);
	imuTaskHandle = osThreadCreate(osThread(imuTask), NULL);

	osThreadDef(led, led_RGB_flow_task, osPriorityNormal, 0, 256);
	led_RGB_flow_handle = osThreadCreate(osThread(led), NULL);

//	  osDelay(3000);
//	  osDelay(3000);
//	  osDelay(3000);

	osThreadDef(Task_Robot_Control, Robot_Control, RobotCtrl_Priority, 0, RobotCtrl_Size);
	RobotCtrl_Handle = osThreadCreate(osThread(Task_Robot_Control), NULL);
	PITCH_trage_angle = DJIC_IMU.total_pitch;
	//

  /* USER CODE END RTOS_THREADS */

}

__weak void test_task(void const * argument)
{
  /* init code for USB_DEVICE */
//  MX_USB_DEVICE_Init();
	for (;;)
	{
		osDelay(1);
	}
}

/* USER CODE BEGIN Header_Debug */
/**
 * @brief Function implementing the Debug_Task thread.
 * @param argument: Not used
 * @retval None
 */
//fp32 voltage;
	uint8_t text_send[5];
	char text_e[5]="A432B";
int YAW_6020_RC_TIMES_100MS;
int PITCH_6020_RC_TIMES_100MS;
int PITCH_6020_RC_TIMES_100MS;
int mag_static=0;
int mag_run_time=0;
int mag_open_times=3000;
int mag_close_times=3000;
int ext_power_heat_data_rc_times_100ms=0;
/* USER CODE END Header_Debug */
void Debug(void const * argument)
{
  /* USER CODE BEGIN Debug */
	int debug_times=0;
	char error_e[5]="error";

	uint16_t range_i=0;
	uint16_t give_i=0;

/*
	char RunTimeInfo[400];		//保存任务运行时间信息

char RunTimeInfo[400];		//保存任务运行时间信息
任务名\t\t\t运行时间\t运行所占百分比
Debug_Task     	427		<1%     反馈给上位机
led            	5866		<1%      led
IDLE           	398036		58%  空闲
IMU_Send_Task  	117005		17%  发给视觉
cali           	63268		9%    校准
test           	455		<1%       什么都没做
Task_Robot_Cont	31306		4%    总控制
Can2_Rei_Task  	463		<1%       CAN2接收
imuTask        	13982		2%    陀螺仪任务
CAN1           	49718		7%    CAN1接收
Tmr Svc        	0		<1%

任务名\t\t\t运行时间\t运行所占百分比
Debug_Task     	4706		<1%
IDLE           	720445		27%
IMU_Send_Task  	1436986		54%
cali           	127828		4%
led            	4709		<1%
test           	457		<1%
Task_Robot_Cont	285106		10%
Tmr Svc        	0		<1%
imuTask        	50511		1%
Can2_Rei_Task  	1		<1%
CAN1           	0		<1%

Debug_Task     	5814		<1%
led            	5804		<1%
IDLE           	885108		27%
IMU_Send_Task  	1764361		54%
cali           	157311		4%
test           	554		<1%
Task_Robot_Cont	350312		10%
Tmr Svc        	0		<1%
imuTask        	62044		1%
Can2_Rei_Task  	1		<1%
CAN1           	0		<1%

		*/
//		buzzer_control.work = TRUE;
	/* Infinite loop */
	for (;;)
	{
		debug_times++;
Get_FPS(&FPS_ALL.DEBUG.WorldTimes,&FPS_ALL.DEBUG.FPS);
		if(debug_times%100==0)
		{
		ext_power_heat_data_rc_times_100ms=HEAT_complete_update_TIMES;
		HEAT_complete_update_TIMES=0;
		}
		if(debug_times%100==0)
		{
			now_speed_0_100=RGB_SEND.RGB_CH0;
			ws2812_init(8);
			get_rgb_value();
			ws2812_blue(8);
		}
						if(debug_times%100==0)//上位机发送频率
				{
if (DR16.rc.s_left == 2)//遥控器左下 弹仓盖测试
{
		    __HAL_TIM_SetCompare(&htim1, TIM_CHANNEL_1, mag_text);	//弹仓舵机失能
}
if (DR16.rc.s_left == 3&&DR16.rc.s_right== 1 )//左中右上 操作手开关舵机
{
	if(keyBoard_B.Press_static==Long_Press&&keyBoard_ctrl.Press_static==No_Press)//Q长按 ctrl不按 开弹仓
	{
				mag_static=1;//1是开弹仓   //开弹仓关激光
	}
	if(keyBoard_B.Press_static==Long_Press&&keyBoard_ctrl.Press_static==Long_Press)//Q长按 ctrl长按 关弹仓
	{
				mag_static=2;//2是关弹仓   //关弹仓开激光
	}
			if(mag_static==1)//1是开弹仓
			{
__HAL_TIM_SetCompare(&htim1, TIM_CHANNEL_1, mag_on);	//开弹仓关激光
mag_run_time+=100;
if(mag_run_time>=mag_open_times)
{
mag_static=0;mag_run_time=0;//结束流程
}
			}
			if(mag_static==2)//2是关弹仓
			{
					    __HAL_TIM_SetCompare(&htim1, TIM_CHANNEL_1, mag_off);	//开弹仓关激光
						mag_run_time+=100;
				if(mag_run_time>=mag_close_times)
				{
				mag_static=0;mag_run_time=0;//结束流程
				}
			}
			if(mag_static==0)//0是失能
			{
		    __HAL_TIM_SetCompare(&htim1, TIM_CHANNEL_1, mag_text);	//关弹仓开激光
			}
}
if (DR16.rc.s_left == 3&&DR16.rc.s_right== 2 )//遥控器左下 弹仓盖测试
{
		if (DR16.rc.ch4_DW <= -200) //拨上
		{
			mag_static=1;//1是开弹仓   //开弹仓关激光
		}
		else if (DR16.rc.ch4_DW >= 200) //拨下
		{
			mag_static=2;//2是关弹仓   //关弹仓开激光
		}
		else
		{
			if(mag_static==1)//1是开弹仓
			{
					    __HAL_TIM_SetCompare(&htim1, TIM_CHANNEL_1, mag_on);	//开弹仓关激光
						mag_run_time+=100;
				if(mag_run_time>=mag_open_times)
				{
				mag_static=0;mag_run_time=0;//结束流程
				}
			}
			if(mag_static==2)//2是关弹仓
			{
					    __HAL_TIM_SetCompare(&htim1, TIM_CHANNEL_1, mag_off);	//开弹仓关激光
						mag_run_time+=100;
				if(mag_run_time>=mag_close_times)
				{
				mag_static=0;mag_run_time=0;//结束流程
				}
			}
			if(mag_static==0)//0是失能
			{
		    __HAL_TIM_SetCompare(&htim1, TIM_CHANNEL_1, mag_text);	//关弹仓开激光
			}
		}
}
				}

				if(debug_times%100==0)//上位机发送频率
				{
				YAW_6020_RC_TIMES_100MS=GM6020s[0].RC_TIMES;
				GM6020s[0].RC_TIMES=0;
					PITCH_6020_RC_TIMES_100MS=GM6020s[3].RC_TIMES;
					GM6020s[3].RC_TIMES=0;
				JS_SHOOT_RC_TIMES_100MSms=JS_SHOOT_RC_TIMES_FOR_FPS;
JS_SHOOT_RC_TIMES_FOR_FPS=0;
				}
				if(debug_times%3==0)//上位机发送频率
						{
							NM_swj();

							//4ms一次
//			printf("好");
						}
		if (DR16.rc.s_right != 2&&DR16.rc.s_right != 0) //是否上位机
		{

			//					USART1->DR = '2';
			//					TRY[0]='0';
			//										TRY[1]='1';

			//	HAL_UART_Transmit_DMA(&huart1,&TRY[0],2);
						if (cali_sensor[0].cali_done == CALIED_FLAG && cali_sensor[0].cali_cmd == 0)
					{

					}
//

		}

		if(debug_times%100==0)//上位机发送频率
		{
		range_i++;
		if(range_i==1)
		{
		text_e[0]='a';
		text_e[1]='9';
		text_e[2]='8';
		text_e[3]='7';
		text_e[4]='b';

		}
		if(range_i==2)
		{
		text_e[0]='c';
		text_e[1]='1';
		text_e[2]='2';
		text_e[3]='3';
		text_e[4]='d';
		range_i=0;
		}
		for(give_i=0;give_i<5;give_i++)
		{
		text_send[give_i]=(char )(text_e[give_i]);
		}

//			CDC_Transmit_FS(&text_send[0],5);
		}

		if(DR16.rc.s_left == 1)
		{
			if(in_END==1&&in_END_last==0)//上一时刻不在轨道末端,这一时刻在轨道末端
			{
		stay_in_track_end_times++;//1ms增加一次
			}
			if(stay_in_track_end_times>0)
			{
			stay_in_track_end_times++;
			}
			if(stay_in_track_end_times>1600)
			{
			stay_in_track_end_times=0;
			}
			if(in_END==0)
			{
			stay_in_track_end_times=0;//这一时刻不在轨道末端了,那肯定就不需要计时了,计时清零
			}
		}
		in_END_last=in_END;
		if(debug_times%100==0)//100ms运行一次

		{
		        //get battery voltage
        //获取电源电压

        my_voltage = get_battery_voltage();
			if(my_voltage<21.8&&my_voltage>20)
			{
			  		if(debug_times%5000==0)//5s运行一次
					{
												Buzzer.mode = One_times;

					}
			}

		}
  		if(debug_times%1000==0)//1s运行一次
		{
//		    oled_clear(Pen_Clear);
//oled_printf(1,1,error_e);
//	    oled_refresh_gram();

		}

   #ifdef FREERTOS_TASK_TIME
		  		if(debug_times%1000==0)//1s运行一次
				{
				memset(RunTimeInfo,0,400);				//信息缓冲区清零

			vTaskGetRunTimeStats(RunTimeInfo);		//获取任务运行时间信息
		  HAL_UART_Transmit_DMA(&huart1, (uint8_t *)&RunTimeInfo, 400);
				}
#endif

//BEEP_TEXT();

		  laoliu_gjiwo_times_ago++;//老六攻击我
		hurt_times_ago++;
				if(ext_robot_hurt.data.hurt_type==0)
		{
			if(ext_robot_hurt.data.armor_id==0||ext_robot_hurt.data.armor_id==1)
			{
				hurt_times_ago=0;//被击中了

			if(ext_robot_hurt.data.armor_id==1)//背面装甲板受击
			{
			laoliu_gjiwo_times_ago=0;//老六攻击我

			}
				ext_robot_hurt.data.hurt_type=10;
			}

		}
		osDelay(1);
	}
  /* USER CODE END Debug */
}

void IMU_Send(void const * argument)
{
  /* USER CODE BEGIN IMU_Send */
	portTickType xLastWakeTime;
	xLastWakeTime = xTaskGetTickCount();
	const TickType_t TimeIncrement = pdMS_TO_TICKS(1); //每十毫秒强制进入总控制
	/* Infinite loop */
	for (;;)
	{
#if send_way == 0
		//欧拉角
//		if (cali_sensor[0].cali_done == CALIED_FLAG && cali_sensor[0].cali_cmd == 0)
//		{
//			Euler_Send.yaw = INS_angle[0];
//			Euler_Send.pitch = INS_angle[1];
//			Euler_Send_Fun(Euler_Send);
//			//角速度
//			Gyro_Send.Gyro_z = INS_gyro[2];
//			Gyro_Send.Gyro_y = INS_gyro[1];
//			Gyro_Send_Fun(Gyro_Send);
//		}
//			DR16_T.DR16_CH0=DR16.rc.ch0=-100;
//			DR16_T.DR16_CH1=DR16.rc.ch1=-200;
//			DR16_T.DR16_CH2=DR16.rc.ch2=-300;
//			DR16_T.DR16_CH3=DR16.rc.ch3=-400;
//		DR16_Send_Fun(DR16_T);

#endif

	CAN_2_SEND_YAW_6020();//yaw轴6020转发函数

		VISION_Disconnect_test++;
		if(VISION_Disconnect_test%100==0)
		{

Update_Vision_SendData();

		}
		if(VISION_Disconnect_test==1000)//一秒检测一次
		{
			if(VisionData.Offline_Detec>10)//一秒接受10次不过分吧
				VisionData.Offline_Detec=0;
			else
			{
				VisionData.Offline_Detec=0;
				VisionData.DataUpdate_Flag=0;//标志位置零
				VisionData.RawData.Beat=0;//击打置零
				VisionData.RawData.Armour=0;//识别置零
				VisionData.RawData.Pitch_Angle=0;
				VisionData.RawData.Yaw_Angle=0;
			}
			VISION_Disconnect_test=0;
		}

		vTaskDelayUntil(&xLastWakeTime, TimeIncrement);
	}
  /* USER CODE END IMU_Send */
}

void Can2_Reivece(void const * argument)
{
  /* USER CODE BEGIN Can2_Reivece */
	/* Infinite loop */
	/* USER CODE BEGIN Can2_Reivece */
	// CAN2接收队列发送的数据的结构体变量
	CAN_Rx_TypeDef CAN2_Rx_Structure;
	//出队的状态变量
	BaseType_t ExitQueue_Status;
int i=0;
	/* Infinite loop */
	for (;;)
	{
		//死等队列有消息
		ExitQueue_Status = xQueueReceive(CAN2_Queue, &CAN2_Rx_Structure, portMAX_DELAY);
		//出队成功
		if (ExitQueue_Status == pdTRUE)
		{
			CAN2_rc_times++;
			can2_DR16_TIMES++;
			//陀螺仪校准指令
			if (CAN2_Rx_Structure.CAN_RxMessage.StdId == IMU_CAL_REIID)
			{
				//解包
				IMU_Cal_Status_Reivece(CAN2_Rx_Structure);
			}

						if (CAN2_Rx_Structure.CAN_RxMessage.StdId == ENCODER_ID)
			{//编码器位置信息解包

								for(i=0;i<8;i++)
				{
				Chassis_Encoder_new.data.dataBuff[i]=CAN2_Rx_Structure.CAN_RxMessageData[i];
				}
				Chassis_Encoder_new.infoUpdateFlag++;
			}
			if (CAN2_Rx_Structure.CAN_RxMessage.StdId == PLACE_SEND_ID)
			{//底盘位置信息解包

				place_complete_update_TIMES++;
								for(i=0;i<8;i++)
				{
				CHASSIS_place[i]=CAN2_Rx_Structure.CAN_RxMessageData[i];
				}

				if(CHASSIS_place[0]==1||CHASSIS_place[7]==1)
				{
					in_END=1;
				}
				if(CHASSIS_place[0]==0&&CHASSIS_place[7]==0)
				{
					in_END=0;
				}

				if(CHASSIS_place[0]==1)
				{
					in_END_L=1;

				}
				else
				{
					in_END_L=0;
				}

				if(CHASSIS_place[7]==1)
				{
					in_END_R=1;

				}
				else
				{
					in_END_R=0;
				}

				if(CHASSIS_place[3]==1||CHASSIS_place[4]==1)
				{
					in_MID=1;
				}
				if(CHASSIS_place[3]==0||CHASSIS_place[4]==0)
				{
					in_MID=0;
				}
					Get_FPS(&FPS_ALL.CHASSIS_PLACE.WorldTimes,   &FPS_ALL.CHASSIS_PLACE.FPS);

			}

						if (CAN2_Rx_Structure.CAN_RxMessage.StdId == JS_SEND_HP_ID_ONE)
			{
				//HP数据解包1
				for(i=0;i<8;i++)
				{
				ext_game_robot_HP.data.dataBuff[i]=CAN2_Rx_Structure.CAN_RxMessageData[i];
				}
				STATUS_PART_ONE_TIMES++;

			}
			if (CAN2_Rx_Structure.CAN_RxMessage.StdId == JS_SEND_HP_ID_TWO)
			{
				//HP数据解包2
				for(i=0;i<8;i++)
				{
				ext_game_robot_HP.data.dataBuff[i+8]=CAN2_Rx_Structure.CAN_RxMessageData[i];

				}
				STATUS_PART_TWO_TIMES++;

			}
			if (CAN2_Rx_Structure.CAN_RxMessage.StdId == JS_SEND_HP_ID_THREE)
			{
				//HP数据解包3
				for(i=0;i<8;i++)
				{
				ext_game_robot_HP.data.dataBuff[i+16]=CAN2_Rx_Structure.CAN_RxMessageData[i];
				}
				STATUS_PART_THREE_TIMES++;
			}
			if (CAN2_Rx_Structure.CAN_RxMessage.StdId == JS_SEND_HP_ID_FOUR)
			{
				//HP数据解包4
				for(i=0;i<8;i++)
				{
				ext_game_robot_HP.data.dataBuff[i+24]=CAN2_Rx_Structure.CAN_RxMessageData[i];
				}
HP_complete_update_TIMES++;
				}

				if (CAN2_Rx_Structure.CAN_RxMessage.StdId == JS_SEND_HGAME_STATE_ID_ONE)
			{
				//热量数据解包1
				for(i=0;i<8;i++)
				{
				ext_game_status.data.dataBuff[i]=CAN2_Rx_Structure.CAN_RxMessageData[i];
				}
			}
			if (CAN2_Rx_Structure.CAN_RxMessage.StdId == JS_SEND_HGAME_STATE_ID_TWO)
			{
				//热量数据解包2
				for(i=0;i<8;i++)
				{
				ext_game_status.data.dataBuff[i+8]=CAN2_Rx_Structure.CAN_RxMessageData[i];
				}
				GAME_STATE_update_TIMES++;
			}

			if (CAN2_Rx_Structure.CAN_RxMessage.StdId == JS_SEND_HEAT_ID_ONE)
			{
				//热量数据解包1
				for(i=0;i<8;i++)
				{
				ext_power_heat_data.data.dataBuff[i]=CAN2_Rx_Structure.CAN_RxMessageData[i];
				}
			}
			if (CAN2_Rx_Structure.CAN_RxMessage.StdId == JS_SEND_HEAT_ID_TWO)
			{
				//热量数据解包2
				for(i=0;i<8;i++)
				{
				ext_power_heat_data.data.dataBuff[i+8]=CAN2_Rx_Structure.CAN_RxMessageData[i];
				}
				HEAT_complete_update_TIMES++;
			}

			if (CAN2_Rx_Structure.CAN_RxMessage.StdId == JS_RC_SHOOT_ID)
			{
				//解包1
				for(i=0;i<8;i++)
				{
				ext_shoot_data.data.dataBuff[i]=CAN2_Rx_Structure.CAN_RxMessageData[i];
				}
				JS_RC_TIMES++;JS_SHOOT_RC_TIMES_FOR_FPS++;
//run_JS_jiema=1;
			}
			if (CAN2_Rx_Structure.CAN_RxMessage.StdId == JS_RC_HURT_ID)
			{
				//解包
				ext_robot_hurt.data.dataBuff[0]=CAN2_Rx_Structure.CAN_RxMessageData[0];
				ext_robot_hurt.InfoUpdataFlag++;
			}

			if (CAN2_Rx_Structure.CAN_RxMessage.StdId == JS_SEND_STATUS_ID_ONE)
			{
				//状态数据解包1
				for(i=0;i<8;i++)
				{
				ext_game_robot_state.data.dataBuff[i]=CAN2_Rx_Structure.CAN_RxMessageData[i];
				}
				STATUS_PART_ONE_TIMES++;

			}
			if (CAN2_Rx_Structure.CAN_RxMessage.StdId == JS_SEND_STATUS_ID_TWO)
			{
				//状态数据解包2
				for(i=0;i<8;i++)
				{
				ext_game_robot_state.data.dataBuff[i+8]=CAN2_Rx_Structure.CAN_RxMessageData[i];

				}
				STATUS_PART_TWO_TIMES++;

			}
			if (CAN2_Rx_Structure.CAN_RxMessage.StdId == JS_SEND_STATUS_ID_THREE)
			{
				//状态数据解包3
				for(i=0;i<8;i++)
				{
				ext_game_robot_state.data.dataBuff[i+16]=CAN2_Rx_Structure.CAN_RxMessageData[i];
				}
				STATUS_PART_THREE_TIMES++;
			}
			if (CAN2_Rx_Structure.CAN_RxMessage.StdId == JS_SEND_STATUS_ID_FOUR)
			{
				//状态数据解包4
				for(i=0;i<8;i++)
				{
				ext_game_robot_state.data.dataBuff[i+24]=CAN2_Rx_Structure.CAN_RxMessageData[i];
				}
				STATUS_PART_FOUR_TIMES++;
STATUS_complete_update_TIMES++;
				}

			if (CAN2_Rx_Structure.CAN_RxMessage.StdId == DR16_R_PART_ONE)
			{
				//解包1
				for(i=0;i<8;i++)
				{
				DR16Buffer[i]=CAN2_Rx_Structure.CAN_RxMessageData[i];
				}
				DDR16_PART_ONE_TIMES++;

			}
			if (CAN2_Rx_Structure.CAN_RxMessage.StdId == DR16_R_PART_TWO)
			{
				//解包2
				for(i=0;i<8;i++)
				{
				DR16Buffer[i+8]=CAN2_Rx_Structure.CAN_RxMessageData[i];

				}
				DDR16_PART_TWO_TIMES++;

			}
			if (CAN2_Rx_Structure.CAN_RxMessage.StdId == DR16_R_PART_THREE)
			{
				//解包3
				for(i=0;i<8;i++)
				{
				DR16Buffer[i+16]=CAN2_Rx_Structure.CAN_RxMessageData[i];
				}
				DDR16_PART_THREE_TIMES++;
				run_DR16_jiema=1;
			}
			if (CAN2_Rx_Structure.CAN_RxMessage.StdId == rgb_send_id)
			{
				//解包3
				for(i=0;i<8;i++)
				{
				RGB_SEND.DR16_SEND[i]=CAN2_Rx_Structure.CAN_RxMessageData[i];
				}
			}
			//rgb_send_id

		}
	}
	//    osDelay(1);
  /* USER CODE END Can2_Reivece */
}

void CAN1_R(void const * argument)
{
  /* USER CODE BEGIN CAN1_R */
	// CAN1接收队列发送的数据的结构体变量
	CAN_Rx_TypeDef CAN1_Rx_Structure;

	//出队的状态变量
	BaseType_t ExitQueue_Status;
	/* Infinite loop */
	for (;;)
	{
		//死等队列有消息
		ExitQueue_Status = xQueueReceive(CAN1_Queue, &CAN1_Rx_Structure, portMAX_DELAY);
		//出队成功

		if (ExitQueue_Status == pdTRUE)
		{
			if (CAN1_Rx_Structure.CAN_RxMessage.StdId == (M3508_READID_START + 3))
			{
				//左摩擦轮的    ID1
				M3508s1_getInfo(CAN1_Rx_Structure); //
			}
			if (CAN1_Rx_Structure.CAN_RxMessage.StdId == (M3508_READID_START + 2))
			{
				//右摩擦轮的	ID2
				M3508s1_getInfo(CAN1_Rx_Structure); //
			}
			if (CAN1_Rx_Structure.CAN_RxMessage.StdId == (M3508_READID_START + 1))
			{
				//拨盘电机		ID3
				M2006_getInfo(CAN1_Rx_Structure); //
			}

			if (CAN1_Rx_Structure.CAN_RxMessage.StdId == GM6020_READID_START)
			{
				//云台
				GM6020_Yaw_getInfo(CAN1_Rx_Structure);
			}

			if (CAN1_Rx_Structure.CAN_RxMessage.StdId == (GM6020_READID_START + 1))//205
			{
				//云台的yaw轴
				GM6020_Pitch_getInfo(CAN1_Rx_Structure); // 6400-7160
			}

			if (CAN1_Rx_Structure.CAN_RxMessage.StdId == GM6020_READID_START + 2)//206
			{
				//云台
				GM6020_Yaw_getInfo(CAN1_Rx_Structure);
			}

			if (CAN1_Rx_Structure.CAN_RxMessage.StdId == GM6020_READID_END)
			{
				//云台的pitch轴3743-4557
				GM6020_Pitch_getInfo(CAN1_Rx_Structure); // 6400-7160
			}
		}
	}
  /* USER CODE END CAN1_R */
}

/* USER CODE BEGIN Application */
uint8_t TRY[20]; //匿名上位机发送数据

int Driver_add = 32768;

void Robot_Control(void const *argument)
{
	/* USER CODE BEGIN RobotControl */
	portTickType xLastWakeTime;
	xLastWakeTime = xTaskGetTickCount();
	const TickType_t TimeIncrement = pdMS_TO_TICKS(1); //每2毫秒强制进入总控制
//    vTaskDelay(1000);
//    vTaskDelay(1000);
//    vTaskDelay(1000);
//    vTaskDelay(1000);
//    vTaskDelay(1000);
//    vTaskDelay(1000);
//    vTaskDelay(1000);
//    vTaskDelay(1000);
//    vTaskDelay(1000);
//    vTaskDelay(1000);
    vTaskDelay(1000);
    vTaskDelay(1000);
	yaw_trage_angle=DJIC_IMU.total_yaw;
	yaw_trage_angle_new=DJIC_IMU.total_yaw;
	PITCH_trage_angle = DJIC_IMU.total_pitch;
M2006_targe_angle=M3508s[1].totalAngle;//清除拨盘目标角度累计

    vTaskDelay(1000);
    vTaskDelay(1000);

	GM6020s[3].turnCount=0;
yaw_trage_angle=DJIC_IMU.total_yaw;
	PITCH_trage_angle = DJIC_IMU.total_pitch;
YAW_MOTION_STATE=1;//开启小陀螺检测
PITCH_trage_angle_motor=GM6020s[3].totalAngle;
//key_message.game_state_progress=4;
//ext_game_status.data.game_progress=4;
//key_message.our_outpost_is_live=1;
	/* Infinite loop */
	for (;;)
	{

				if(run_DR16_jiema==1)
		{
							DR16.DR16_Process(DR16Buffer);
					keyBoard_QE();
			keyBoard_shift_ctrl();
			mouse_Left_Right();
			run_DR16_jiema=0;
		}
			#if SHOOT_HIGH_HEAT_TEXT
		vision_shoot_times=100;
VisionData.RawData.Armour=1;
				if(controul_times%200==0)
		{
	VisionData.RawData.Beat=1;
		}
		else
		{
				VisionData.RawData.Beat=0;
	}
//VisionData.RawData.Beat=1;
	Vision_RawData_Pitch_Angle=0;
	Vision_RawData_Yaw_Angle=0;
#endif

						Vision_Control_Cloud();

								if (DR16.rc.s_left == 2&&DR16.rc.ch3<-600) //失能保护
				{
					disable_for_test_CHASSIS=1;
				}
				if (DR16.rc.s_left == 2&&DR16.rc.ch3>600) //失能保护
				{
					disable_for_test_CHASSIS=0;
				}
		if(controul_times%1000==0)
		{
			yaw_trage_angle_add_1s=yaw_trage_angle-yaw_trage_angle_1s_ago;
			yaw_trage_angle_1s_ago=yaw_trage_angle;
		}
		if(controul_times%10==0)
		{
			 if(DR16.rc.s_left==3&&DR16.rc.s_right==3)
			 {
//		yaw_trage_angle=simulation_target_yaw;
			 }
		}
//				if (DR16.rc.s_left == 2&&DR16.rc.ch1<-600) //失能保护
//				{
//					disable_for_test=1;
//				}
//				if (DR16.rc.s_left == 2&&DR16.rc.ch1>600) //失能保护
//				{
//					disable_for_test=0;
//				}

				if(VisionData.RawData.Armour==0)//
				{
		Armour_lose_time++;
				}
			else if(VisionData.RawData.Armour==1)//
				{
		Armour_lose_time=0;
				}

				controul_times++;
				S_T_examine();
		cloud_control();

#if use_new_gimbal==0
		if (GM6020s[3].totalAngle <= 3860 && send_to_pitch < 0)//3860
			send_to_pitch = 0;
		if (GM6020s[3].totalAngle >= 5130 && send_to_pitch > 0)
			send_to_pitch = 0;
#endif
#if use_new_gimbal==1

		if (GM6020s[3].totalAngle <= 5150 && send_to_pitch < 0)//3860
			send_to_pitch = 0;
		if (GM6020s[3].totalAngle >= 6550 && send_to_pitch > 0)
			send_to_pitch = 0;
#endif
#if use_balance_gimbal==1

		if (GM6020s[3].totalAngle <= 4600 && send_to_pitch < 0)//3860
			send_to_pitch = 0;
		if (GM6020s[3].totalAngle >= 5850 && send_to_pitch > 0)
			send_to_pitch = 0;
#endif
		//云台的pitch轴正直是往上的
		////8017-7044
//			send_to_yaw = 0;

		if (DR16.rc.s_left == 2 || DR16.rc.s_left == 0) //失能保护
		{
			send_to_pitch = 0;
			send_to_yaw = 0;
yaw_trage_angle_new=DJIC_IMU.total_yaw;
			yaw_trage_angle_new_2=yaw_trage_angle_new;
			PITCH_trage_angle=DJIC_IMU.total_pitch;
			yaw_trage_angle=DJIC_IMU.total_yaw;
			PITCH_trage_angle_motor=GM6020s[3].totalAngle;
			//还不够，使能瞬间会抖一下，应该还要清楚I的累加，以后有时间再写
		}
		if(disable_for_test==1)
		{
				send_to_yaw = 0;
				send_to_pitch = 0;

		}

		GM6020_SetVoltage(send_to_yaw,0 , 0, send_to_pitch); //云台  send_to_pitch  下下上下
//		GM6020_SetVoltage(0,0 , 0, 0); //云台  send_to_pitch

		//	if(DR16.rc.s_left==1)//遥控器控制  左上
		// SHOOT_L_speed=500;
		//	if(DR16.rc.s_left==3)//遥控器控制  左中
		//					{
		////SHOOT_L_speed=(DR16.rc.ch3*1.0/660.0)*(-1)*8000;//遥控器给速度目标值 二选一
		// if(DR16.rc.ch3<-600)
		//			SHOOT_L_speed=6700;
		// else
		//				SHOOT_L_speed=0;

		//						}
		//				SHOOT_R_speed=SHOOT_L_speed;
		//		if(	SHOOT_L_speed>0)
		//		SHOOT_L_speed=-SHOOT_L_speed;//左摩擦轮速度目标值应该是负值
		//		if(	SHOOT_R_speed<0)
		//		SHOOT_R_speed=-SHOOT_R_speed;//右摩擦轮速度目标值应该是正值
		// send_to_SHOOT_L=I_PID_Regulation(&SHOOT_L_I_PID,SHOOT_R_speed,M3508s[3].realSpeed);

		// send_to_SHOOT_R=I_PID_Regulation(&SHOOT_R_I_PID,SHOOT_L_speed,M3508s[2].realSpeed);
		//

		shoot_control();
//	shoot_control_V2();
		if (DR16.rc.s_left == 2 || DR16.rc.s_left == 0) //失能保护
		{
			//						send_to_chassis=0;
	send_to_SHOOT_L = 0;
			send_to_SHOOT_R = 0;
	GM6020s[3].turnCount=0;
DJIC_IMU.yaw_turnCounts=0;
			send_to_2006 = 0;
			//						send_to_yaw=0;
			//						M2006_targe_angle=M3508s[1].totalAngle;//摩擦轮误差消除
		}
				if(disable_for_test==1)
		{
								send_to_SHOOT_L = 0;
			send_to_SHOOT_R = 0;
						send_to_2006 = 0;

		}

		M3508s1_setCurrent(0, send_to_2006, send_to_SHOOT_R, send_to_SHOOT_L);//send_to_SHOOT_L阻力大
//		M3508s1_setCurrent(0, 0,TEST_Current_R ,TEST_Current_L );  //end_to_SHOOT_R给正降得慢
        //                                    +                 -
		vTaskDelayUntil(&xLastWakeTime, TimeIncrement);

	}

	/* USER CODE END RobotControl */
}
/* USER CODE END Application */

/************************ (C) COPYRIGHT STMicroelectronics *****END OF FILE****/
